AUTOSAR XML (schema 4-1-3)
standard types defined: boolean, uint8
package /UAES/ASW/CompuMethods
  compu method CM_boolean: 0=FALSE, 1=TRUE
package /UAES/ASW/DataConstrs
  range DC_boolean: raw 0..1
package /UAES/ASW/DataTypeMappingSets
  data type mapping set DTMS_HVAC_ComCnvRx
package /UAES/ASW/PortInterfaces
  53 x sender receiver interface:
    ComRx_bHVAC_AirCirculationReqVD: invalidation-policy{data-element=ComRx_bHVAC_AirCirculationReqVD/Val, handle-invalid=DONT-INVALIDATE}
      data Val: sw-calibration-access=READ-ONLY, type=boolean
    ComRx_bHVAC_DrAirCirculationReqVD: invalidation-policy{data-element=ComRx_bHVAC_DrAirCirculationReqVD/Val, handle-invalid=DONT-INVALIDATE}
      data Val: sw-calibration-access=READ-ONLY, type=boolean
    ComRx_bHVAC_DrAMDoorPostionVD: invalidation-policy{data-element=ComRx_bHVAC_DrAMDoorPostionVD/Val, handle-invalid=DONT-INVALIDATE}
      data Val: sw-calibration-access=READ-ONLY, type=boolean
    ComRx_bHVAC_PaAirCirculationReqVD: invalidation-policy{data-element=ComRx_bHVAC_PaAirCirculationReqVD/Val, handle-invalid=DONT-INVALIDATE}
      data Val: sw-calibration-access=READ-ONLY, type=boolean
    ComRx_bHVAC_PaAMDoorPostionVD: invalidation-policy{data-element=ComRx_bHVAC_PaAMDoorPostionVD/Val, handle-invalid=DONT-INVALIDATE}
      data Val: sw-calibration-access=READ-ONLY, type=boolean
    ComRx_bHVAC_RearAMDoorPosVD: invalidation-policy{data-element=ComRx_bHVAC_RearAMDoorPosVD/Val, handle-invalid=DONT-INVALIDATE}
      data Val: sw-calibration-access=READ-ONLY, type=boolean
    ComRx_bHVAC_RearDefrostSt: invalidation-policy{data-element=ComRx_bHVAC_RearDefrostSt/Val, handle-invalid=DONT-INVALIDATE}
      data Val: sw-calibration-access=READ-ONLY, type=boolean
    ComRx_bHVAC_RearWindExitModeReqVD: invalidation-policy{data-element=ComRx_bHVAC_RearWindExitModeReqVD/Val, handle-invalid=DONT-INVALIDATE}
      data Val: sw-calibration-access=READ-ONLY, type=boolean
    ComRx_bHVAC_WindExitModeReqVD: invalidation-policy{data-element=ComRx_bHVAC_WindExitModeReqVD/Val, handle-invalid=DONT-INVALIDATE}
      data Val: sw-calibration-access=READ-ONLY, type=boolean
    ComRx_u8HVAC_AirCirculationReq: invalidation-policy{data-element=ComRx_u8HVAC_AirCirculationReq/Val, handle-invalid=DONT-INVALIDATE}
      data Val: sw-calibration-access=READ-ONLY, type=uint8
    ComRx_u8HVAC_AirCirculationSt: invalidation-policy{data-element=ComRx_u8HVAC_AirCirculationSt/Val, handle-invalid=DONT-INVALIDATE}
      data Val: sw-calibration-access=READ-ONLY, type=uint8
    ComRx_u8HVAC_DrAirCirculationReq: invalidation-policy{data-element=ComRx_u8HVAC_DrAirCirculationReq/Val, handle-invalid=DONT-INVALIDATE}
      data Val: sw-calibration-access=READ-ONLY, type=uint8
    ComRx_u8HVAC_DrAMDoorPostion: invalidation-policy{data-element=ComRx_u8HVAC_DrAMDoorPostion/Val, handle-invalid=DONT-INVALIDATE}
      data Val: sw-calibration-access=READ-ONLY, type=uint8
    ComRx_u8HVAC_PaAirCirculationReq: invalidation-policy{data-element=ComRx_u8HVAC_PaAirCirculationReq/Val, handle-invalid=DONT-INVALIDATE}
      data Val: sw-calibration-access=READ-ONLY, type=uint8
    ComRx_u8HVAC_PaAMDoorPostion: invalidation-policy{data-element=ComRx_u8HVAC_PaAMDoorPostion/Val, handle-invalid=DONT-INVALIDATE}
      data Val: sw-calibration-access=READ-ONLY, type=uint8
    ComRx_u8HVAC_RearAMDoorPos: invalidation-policy{data-element=ComRx_u8HVAC_RearAMDoorPos/Val, handle-invalid=DONT-INVALIDATE}
      data Val: sw-calibration-access=READ-ONLY, type=uint8
    ComRx_u8HVAC_RearWindExitModeReq: invalidation-policy{data-element=ComRx_u8HVAC_RearWindExitModeReq/Val, handle-invalid=DONT-INVALIDATE}
      data Val: sw-calibration-access=READ-ONLY, type=uint8
    ComRx_u8HVAC_RearWindExitSpdLvl: invalidation-policy{data-element=ComRx_u8HVAC_RearWindExitSpdLvl/Val, handle-invalid=DONT-INVALIDATE}
      data Val: sw-calibration-access=READ-ONLY, type=uint8
    ComRx_u8HVAC_WindExitMode: invalidation-policy{data-element=ComRx_u8HVAC_WindExitMode/Val, handle-invalid=DONT-INVALIDATE}
      data Val: sw-calibration-access=READ-ONLY, type=uint8
    ComRx_u8HVAC_WindExitModeReq: invalidation-policy{data-element=ComRx_u8HVAC_WindExitModeReq/Val, handle-invalid=DONT-INVALIDATE}
      data Val: sw-calibration-access=READ-ONLY, type=uint8
    ComRx_u8HVAC_WindExitSpd: invalidation-policy{data-element=ComRx_u8HVAC_WindExitSpd/Val, handle-invalid=DONT-INVALIDATE}
      data Val: sw-calibration-access=READ-ONLY, type=uint8
    ComRx_u8HVAC_WindExitSpdLvl: invalidation-policy{data-element=ComRx_u8HVAC_WindExitSpdLvl/Val, handle-invalid=DONT-INVALIDATE}
      data Val: sw-calibration-access=READ-ONLY, type=uint8
    ComRx_u8UMM_UsageModeSt: invalidation-policy{data-element=ComRx_u8UMM_UsageModeSt/Val, handle-invalid=DONT-INVALIDATE}
      data Val: sw-calibration-access=READ-ONLY, type=uint8
    gASI_bCCULostCommon: invalidation-policy{data-element=gASI_bCCULostCommon/Val, handle-invalid=DONT-INVALIDATE}
      data Val: sw-calibration-access=READ-ONLY, type=boolean
    gCFG_u8BlowrCtrlFreqTyp: invalidation-policy{data-element=gCFG_u8BlowrCtrlFreqTyp/Val, handle-invalid=DONT-INVALIDATE}
      data Val: sw-calibration-access=READ-ONLY, type=uint8
    gCFG_u8BlowrCtrlTyp: invalidation-policy{data-element=gCFG_u8BlowrCtrlTyp/Val, handle-invalid=DONT-INVALIDATE}
      data Val: sw-calibration-access=READ-ONLY, type=uint8
    gCFG_u8ReBlowrCtrlFreqTyp: invalidation-policy{data-element=gCFG_u8ReBlowrCtrlFreqTyp/Val, handle-invalid=DONT-INVALIDATE}
      data Val: sw-calibration-access=READ-ONLY, type=uint8
    gCFG_u8ReBlowrCtrlTyp: invalidation-policy{data-element=gCFG_u8ReBlowrCtrlTyp/Val, handle-invalid=DONT-INVALIDATE}
      data Val: sw-calibration-access=READ-ONLY, type=uint8
    gCFG_u8ReHVACBoxTyp: invalidation-policy{data-element=gCFG_u8ReHVACBoxTyp/Val, handle-invalid=DONT-INVALIDATE}
      data Val: sw-calibration-access=READ-ONLY, type=uint8
    gPRM_u8AirConditionBoxSpecCfg: invalidation-policy{data-element=gPRM_u8AirConditionBoxSpecCfg/Val, handle-invalid=DONT-INVALIDATE}
      data Val: sw-calibration-access=READ-ONLY, type=uint8
    gPRM_u8ReAirConditionBoxSpecCfg: invalidation-policy{data-element=gPRM_u8ReAirConditionBoxSpecCfg/Val, handle-invalid=DONT-INVALIDATE}
      data Val: sw-calibration-access=READ-ONLY, type=uint8
    gPRM_u8VehicleTypeCfg: invalidation-policy{data-element=gPRM_u8VehicleTypeCfg/Val, handle-invalid=DONT-INVALIDATE}
      data Val: sw-calibration-access=READ-ONLY, range raw 0..255, type=uint8
    HvacBlowr_stReWindExitSpdLvl: invalidation-policy{data-element=HvacBlowr_stReWindExitSpdLvl/Val, handle-invalid=DONT-INVALIDATE}
      data Val: sw-calibration-access=READ-ONLY, type=uint8
    HvacBlowr_stWindExitSpdLvl: invalidation-policy{data-element=HvacBlowr_stWindExitSpdLvl/Val, handle-invalid=DONT-INVALIDATE}
      data Val: sw-calibration-access=READ-ONLY, type=uint8
    HvacDampr_bReqVldDrvrMixMot: invalidation-policy{data-element=HvacDampr_bReqVldDrvrMixMot/Val, handle-invalid=DONT-INVALIDATE}
      data Val: sw-calibration-access=READ-ONLY, type=boolean
    HvacDampr_bReqVldDrvrRcrltnMot: invalidation-policy{data-element=HvacDampr_bReqVldDrvrRcrltnMot/Val, handle-invalid=DONT-INVALIDATE}
      data Val: sw-calibration-access=READ-ONLY, type=boolean
    HvacDampr_bReqVldMotMot: invalidation-policy{data-element=HvacDampr_bReqVldMotMot/Val, handle-invalid=DONT-INVALIDATE}
      data Val: sw-calibration-access=READ-ONLY, type=boolean
    HvacDampr_bReqVldPassMixMot: invalidation-policy{data-element=HvacDampr_bReqVldPassMixMot/Val, handle-invalid=DONT-INVALIDATE}
      data Val: sw-calibration-access=READ-ONLY, type=boolean
    HvacDampr_bReqVldPassRcrltnMot: invalidation-policy{data-element=HvacDampr_bReqVldPassRcrltnMot/Val, handle-invalid=DONT-INVALIDATE}
      data Val: sw-calibration-access=READ-ONLY, type=boolean
    HvacDampr_bReqVldRcrltnMot: invalidation-policy{data-element=HvacDampr_bReqVldRcrltnMot/Val, handle-invalid=DONT-INVALIDATE}
      data Val: sw-calibration-access=READ-ONLY, type=boolean
    HvacDampr_bReqVldReMixMot: invalidation-policy{data-element=HvacDampr_bReqVldReMixMot/Val, handle-invalid=DONT-INVALIDATE}
      data Val: sw-calibration-access=READ-ONLY, type=boolean
    HvacDampr_bReqVldReMotMot: invalidation-policy{data-element=HvacDampr_bReqVldReMotMot/Val, handle-invalid=DONT-INVALIDATE}
      data Val: sw-calibration-access=READ-ONLY, type=boolean
    HvacDampr_stReqDrvrMixMot: invalidation-policy{data-element=HvacDampr_stReqDrvrMixMot/Val, handle-invalid=DONT-INVALIDATE}
      data Val: sw-calibration-access=READ-ONLY, type=uint8
    HvacDampr_stReqDrvrRcrltnMot: invalidation-policy{data-element=HvacDampr_stReqDrvrRcrltnMot/Val, handle-invalid=DONT-INVALIDATE}
      data Val: sw-calibration-access=READ-ONLY, type=uint8
    HvacDampr_stReqMotMot: invalidation-policy{data-element=HvacDampr_stReqMotMot/Val, handle-invalid=DONT-INVALIDATE}
      data Val: sw-calibration-access=READ-ONLY, type=uint8
    HvacDampr_stReqPassMixMot: invalidation-policy{data-element=HvacDampr_stReqPassMixMot/Val, handle-invalid=DONT-INVALIDATE}
      data Val: sw-calibration-access=READ-ONLY, type=uint8
    HvacDampr_stReqPassRcrltnMot: invalidation-policy{data-element=HvacDampr_stReqPassRcrltnMot/Val, handle-invalid=DONT-INVALIDATE}
      data Val: sw-calibration-access=READ-ONLY, type=uint8
    HvacDampr_stReqRcrltnMot: invalidation-policy{data-element=HvacDampr_stReqRcrltnMot/Val, handle-invalid=DONT-INVALIDATE}
      data Val: sw-calibration-access=READ-ONLY, type=uint8
    HvacDampr_stReqReMixMot: invalidation-policy{data-element=HvacDampr_stReqReMixMot/Val, handle-invalid=DONT-INVALIDATE}
      data Val: sw-calibration-access=READ-ONLY, type=uint8
    HvacDampr_stReqReMotMot: invalidation-policy{data-element=HvacDampr_stReqReMotMot/Val, handle-invalid=DONT-INVALIDATE}
      data Val: sw-calibration-access=READ-ONLY, type=uint8
    ReMirrHeatg_stReqLe: invalidation-policy{data-element=ReMirrHeatg_stReqLe/Val, handle-invalid=DONT-INVALIDATE}
      data Val: sw-calibration-access=READ-ONLY, type=uint8
    ReMirrHeatg_stReqRi: invalidation-policy{data-element=ReMirrHeatg_stReqRi/Val, handle-invalid=DONT-INVALIDATE}
      data Val: sw-calibration-access=READ-ONLY, type=uint8
    WndshdHeatg_stReqRe: invalidation-policy{data-element=WndshdHeatg_stReqRe/Val, handle-invalid=DONT-INVALIDATE}
      data Val: sw-calibration-access=READ-ONLY, type=uint8
package /UAES/ASW/SwComponentTypes
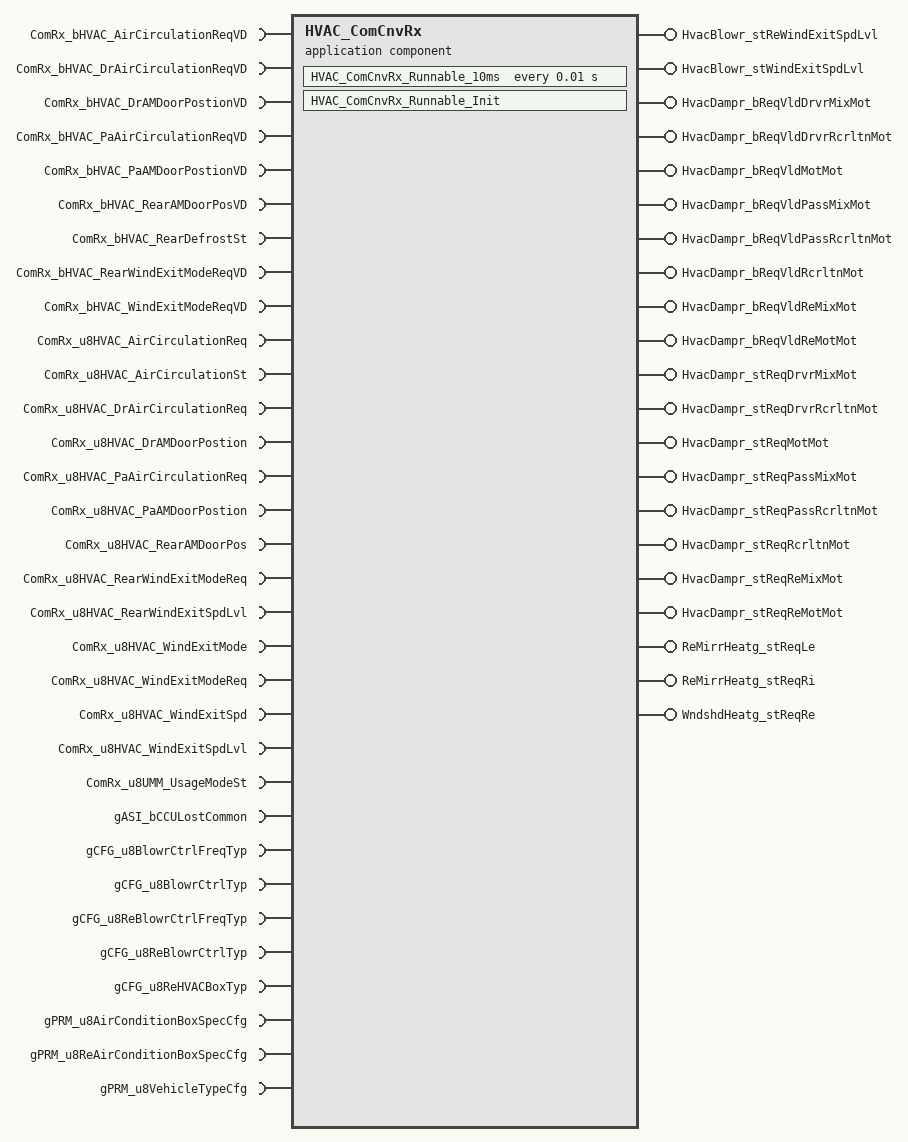
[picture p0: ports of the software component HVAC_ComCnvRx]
  application sw component type HVAC_ComCnvRx
    21 x provide port:
      HvacBlowr_stReWindExitSpdLvl: nonqueued-sender-com-spec{data-element=HvacBlowr_stReWindExitSpdLvl/Val, init-value=0}, provided-interface=HvacBlowr_stReWindExitSpdLvl
      HvacBlowr_stWindExitSpdLvl: nonqueued-sender-com-spec{data-element=HvacBlowr_stWindExitSpdLvl/Val, init-value=0}, provided-interface=HvacBlowr_stWindExitSpdLvl
      HvacDampr_bReqVldDrvrMixMot: nonqueued-sender-com-spec{data-element=HvacDampr_bReqVldDrvrMixMot/Val, init-value=0}, provided-interface=HvacDampr_bReqVldDrvrMixMot
      HvacDampr_bReqVldDrvrRcrltnMot: nonqueued-sender-com-spec{data-element=HvacDampr_bReqVldDrvrRcrltnMot/Val, init-value=0}, provided-interface=HvacDampr_bReqVldDrvrRcrltnMot
      HvacDampr_bReqVldMotMot: nonqueued-sender-com-spec{data-element=HvacDampr_bReqVldMotMot/Val, init-value=0}, provided-interface=HvacDampr_bReqVldMotMot
      HvacDampr_bReqVldPassMixMot: nonqueued-sender-com-spec{data-element=HvacDampr_bReqVldPassMixMot/Val, init-value=0}, provided-interface=HvacDampr_bReqVldPassMixMot
      HvacDampr_bReqVldPassRcrltnMot: nonqueued-sender-com-spec{data-element=HvacDampr_bReqVldPassRcrltnMot/Val, init-value=0}, provided-interface=HvacDampr_bReqVldPassRcrltnMot
      HvacDampr_bReqVldRcrltnMot: nonqueued-sender-com-spec{data-element=HvacDampr_bReqVldRcrltnMot/Val, init-value=0}, provided-interface=HvacDampr_bReqVldRcrltnMot
      HvacDampr_bReqVldReMixMot: nonqueued-sender-com-spec{data-element=HvacDampr_bReqVldReMixMot/Val, init-value=0}, provided-interface=HvacDampr_bReqVldReMixMot
      HvacDampr_bReqVldReMotMot: nonqueued-sender-com-spec{data-element=HvacDampr_bReqVldReMotMot/Val, init-value=0}, provided-interface=HvacDampr_bReqVldReMotMot
      HvacDampr_stReqDrvrMixMot: nonqueued-sender-com-spec{data-element=HvacDampr_stReqDrvrMixMot/Val, init-value=0}, provided-interface=HvacDampr_stReqDrvrMixMot
      HvacDampr_stReqDrvrRcrltnMot: nonqueued-sender-com-spec{data-element=HvacDampr_stReqDrvrRcrltnMot/Val, init-value=0}, provided-interface=HvacDampr_stReqDrvrRcrltnMot
      HvacDampr_stReqMotMot: nonqueued-sender-com-spec{data-element=HvacDampr_stReqMotMot/Val, init-value=0}, provided-interface=HvacDampr_stReqMotMot
      HvacDampr_stReqPassMixMot: nonqueued-sender-com-spec{data-element=HvacDampr_stReqPassMixMot/Val, init-value=0}, provided-interface=HvacDampr_stReqPassMixMot
      HvacDampr_stReqPassRcrltnMot: nonqueued-sender-com-spec{data-element=HvacDampr_stReqPassRcrltnMot/Val, init-value=0}, provided-interface=HvacDampr_stReqPassRcrltnMot
      HvacDampr_stReqRcrltnMot: nonqueued-sender-com-spec{data-element=HvacDampr_stReqRcrltnMot/Val, init-value=0}, provided-interface=HvacDampr_stReqRcrltnMot
      HvacDampr_stReqReMixMot: nonqueued-sender-com-spec{data-element=HvacDampr_stReqReMixMot/Val, init-value=0}, provided-interface=HvacDampr_stReqReMixMot
      HvacDampr_stReqReMotMot: nonqueued-sender-com-spec{data-element=HvacDampr_stReqReMotMot/Val, init-value=0}, provided-interface=HvacDampr_stReqReMotMot
      ReMirrHeatg_stReqLe: nonqueued-sender-com-spec{data-element=ReMirrHeatg_stReqLe/Val, init-value=0}, provided-interface=ReMirrHeatg_stReqLe
      ReMirrHeatg_stReqRi: nonqueued-sender-com-spec{data-element=ReMirrHeatg_stReqRi/Val, init-value=0}, provided-interface=ReMirrHeatg_stReqRi
      WndshdHeatg_stReqRe: nonqueued-sender-com-spec{data-element=WndshdHeatg_stReqRe/Val, init-value=0}, provided-interface=WndshdHeatg_stReqRe
    32 x require port:
      ComRx_bHVAC_AirCirculationReqVD: nonqueued-receiver-com-spec{data-element=ComRx_bHVAC_AirCirculationReqVD/Val, filter=data-filter-type=ALWAYS, init-value=0}, required-interface=ComRx_bHVAC_AirCirculationReqVD
      ComRx_bHVAC_DrAirCirculationReqVD: nonqueued-receiver-com-spec{data-element=ComRx_bHVAC_DrAirCirculationReqVD/Val, filter=data-filter-type=ALWAYS, init-value=0}, required-interface=ComRx_bHVAC_DrAirCirculationReqVD
      ComRx_bHVAC_DrAMDoorPostionVD: nonqueued-receiver-com-spec{data-element=ComRx_bHVAC_DrAMDoorPostionVD/Val, filter=data-filter-type=ALWAYS, init-value=0}, required-interface=ComRx_bHVAC_DrAMDoorPostionVD
      ComRx_bHVAC_PaAirCirculationReqVD: nonqueued-receiver-com-spec{data-element=ComRx_bHVAC_PaAirCirculationReqVD/Val, filter=data-filter-type=ALWAYS, init-value=0}, required-interface=ComRx_bHVAC_PaAirCirculationReqVD
      ComRx_bHVAC_PaAMDoorPostionVD: nonqueued-receiver-com-spec{data-element=ComRx_bHVAC_PaAMDoorPostionVD/Val, filter=data-filter-type=ALWAYS, init-value=0}, required-interface=ComRx_bHVAC_PaAMDoorPostionVD
      ComRx_bHVAC_RearAMDoorPosVD: nonqueued-receiver-com-spec{data-element=ComRx_bHVAC_RearAMDoorPosVD/Val, filter=data-filter-type=ALWAYS, init-value=0}, required-interface=ComRx_bHVAC_RearAMDoorPosVD
      ComRx_bHVAC_RearDefrostSt: nonqueued-receiver-com-spec{data-element=ComRx_bHVAC_RearDefrostSt/Val, filter=data-filter-type=ALWAYS, init-value=0}, required-interface=ComRx_bHVAC_RearDefrostSt
      ComRx_bHVAC_RearWindExitModeReqVD: nonqueued-receiver-com-spec{data-element=ComRx_bHVAC_RearWindExitModeReqVD/Val, filter=data-filter-type=ALWAYS, init-value=0}, required-interface=ComRx_bHVAC_RearWindExitModeReqVD
      ComRx_bHVAC_WindExitModeReqVD: nonqueued-receiver-com-spec{data-element=ComRx_bHVAC_WindExitModeReqVD/Val, filter=data-filter-type=ALWAYS, init-value=0}, required-interface=ComRx_bHVAC_WindExitModeReqVD
      ComRx_u8HVAC_AirCirculationReq: nonqueued-receiver-com-spec{data-element=ComRx_u8HVAC_AirCirculationReq/Val, filter=data-filter-type=ALWAYS, init-value=0}, required-interface=ComRx_u8HVAC_AirCirculationReq
      ComRx_u8HVAC_AirCirculationSt: nonqueued-receiver-com-spec{data-element=ComRx_u8HVAC_AirCirculationSt/Val, filter=data-filter-type=ALWAYS, init-value=0}, required-interface=ComRx_u8HVAC_AirCirculationSt
      ComRx_u8HVAC_DrAirCirculationReq: nonqueued-receiver-com-spec{data-element=ComRx_u8HVAC_DrAirCirculationReq/Val, filter=data-filter-type=ALWAYS, init-value=0}, required-interface=ComRx_u8HVAC_DrAirCirculationReq
      ComRx_u8HVAC_DrAMDoorPostion: nonqueued-receiver-com-spec{data-element=ComRx_u8HVAC_DrAMDoorPostion/Val, filter=data-filter-type=ALWAYS, init-value=0}, required-interface=ComRx_u8HVAC_DrAMDoorPostion
      ComRx_u8HVAC_PaAirCirculationReq: nonqueued-receiver-com-spec{data-element=ComRx_u8HVAC_PaAirCirculationReq/Val, filter=data-filter-type=ALWAYS, init-value=0}, required-interface=ComRx_u8HVAC_PaAirCirculationReq
      ComRx_u8HVAC_PaAMDoorPostion: nonqueued-receiver-com-spec{data-element=ComRx_u8HVAC_PaAMDoorPostion/Val, filter=data-filter-type=ALWAYS, init-value=0}, required-interface=ComRx_u8HVAC_PaAMDoorPostion
      ComRx_u8HVAC_RearAMDoorPos: nonqueued-receiver-com-spec{data-element=ComRx_u8HVAC_RearAMDoorPos/Val, filter=data-filter-type=ALWAYS, init-value=0}, required-interface=ComRx_u8HVAC_RearAMDoorPos
      ComRx_u8HVAC_RearWindExitModeReq: nonqueued-receiver-com-spec{data-element=ComRx_u8HVAC_RearWindExitModeReq/Val, filter=data-filter-type=ALWAYS, init-value=0}, required-interface=ComRx_u8HVAC_RearWindExitModeReq
      ComRx_u8HVAC_RearWindExitSpdLvl: nonqueued-receiver-com-spec{data-element=ComRx_u8HVAC_RearWindExitSpdLvl/Val, filter=data-filter-type=ALWAYS, init-value=0}, required-interface=ComRx_u8HVAC_RearWindExitSpdLvl
      ComRx_u8HVAC_WindExitMode: nonqueued-receiver-com-spec{data-element=ComRx_u8HVAC_WindExitMode/Val, filter=data-filter-type=ALWAYS, init-value=0}, required-interface=ComRx_u8HVAC_WindExitMode
      ComRx_u8HVAC_WindExitModeReq: nonqueued-receiver-com-spec{data-element=ComRx_u8HVAC_WindExitModeReq/Val, filter=data-filter-type=ALWAYS, init-value=0}, required-interface=ComRx_u8HVAC_WindExitModeReq
      ComRx_u8HVAC_WindExitSpd: nonqueued-receiver-com-spec{data-element=ComRx_u8HVAC_WindExitSpd/Val, filter=data-filter-type=ALWAYS, init-value=0}, required-interface=ComRx_u8HVAC_WindExitSpd
      ComRx_u8HVAC_WindExitSpdLvl: nonqueued-receiver-com-spec{data-element=ComRx_u8HVAC_WindExitSpdLvl/Val, filter=data-filter-type=ALWAYS, init-value=0}, required-interface=ComRx_u8HVAC_WindExitSpdLvl
      ComRx_u8UMM_UsageModeSt: nonqueued-receiver-com-spec{data-element=ComRx_u8UMM_UsageModeSt/Val, filter=data-filter-type=ALWAYS, init-value=0}, required-interface=ComRx_u8UMM_UsageModeSt
      gASI_bCCULostCommon: nonqueued-receiver-com-spec{data-element=gASI_bCCULostCommon/Val, filter=data-filter-type=ALWAYS, init-value=0}, required-interface=gASI_bCCULostCommon
      gCFG_u8BlowrCtrlFreqTyp: nonqueued-receiver-com-spec{data-element=gCFG_u8BlowrCtrlFreqTyp/Val, filter=data-filter-type=ALWAYS, init-value=0}, required-interface=gCFG_u8BlowrCtrlFreqTyp
      gCFG_u8BlowrCtrlTyp: nonqueued-receiver-com-spec{data-element=gCFG_u8BlowrCtrlTyp/Val, filter=data-filter-type=ALWAYS, init-value=0}, required-interface=gCFG_u8BlowrCtrlTyp
      gCFG_u8ReBlowrCtrlFreqTyp: nonqueued-receiver-com-spec{data-element=gCFG_u8ReBlowrCtrlFreqTyp/Val, filter=data-filter-type=ALWAYS, init-value=0}, required-interface=gCFG_u8ReBlowrCtrlFreqTyp
      gCFG_u8ReBlowrCtrlTyp: nonqueued-receiver-com-spec{data-element=gCFG_u8ReBlowrCtrlTyp/Val, filter=data-filter-type=ALWAYS, init-value=0}, required-interface=gCFG_u8ReBlowrCtrlTyp
      gCFG_u8ReHVACBoxTyp: nonqueued-receiver-com-spec{data-element=gCFG_u8ReHVACBoxTyp/Val, filter=data-filter-type=ALWAYS, init-value=0}, required-interface=gCFG_u8ReHVACBoxTyp
      gPRM_u8AirConditionBoxSpecCfg: nonqueued-receiver-com-spec{data-element=gPRM_u8AirConditionBoxSpecCfg/Val, filter=data-filter-type=ALWAYS, init-value=0}, required-interface=gPRM_u8AirConditionBoxSpecCfg
      gPRM_u8ReAirConditionBoxSpecCfg: nonqueued-receiver-com-spec{data-element=gPRM_u8ReAirConditionBoxSpecCfg/Val, filter=data-filter-type=ALWAYS, init-value=0}, required-interface=gPRM_u8ReAirConditionBoxSpecCfg
      gPRM_u8VehicleTypeCfg: nonqueued-receiver-com-spec{data-element=gPRM_u8VehicleTypeCfg/Val, filter=data-filter-type=ALWAYS, init-value=0}, required-interface=gPRM_u8VehicleTypeCfg
    behavior HVAC_ComCnvRx_InternalBehavior: data-type-mapping=DTMS_HVAC_ComCnvRx
      timing event TMT_HVAC_ComCnvRx_Runnable_10ms: start-on-event=HVAC_ComCnvRx_Runnable_10ms, period=0.01
      init event HVAC_ComCnvRx_Runnable_InitEvent: start-on-event=HVAC_ComCnvRx_Runnable_Init
      runnable HVAC_ComCnvRx_Runnable_10ms
        data-receive-point-by-arguments:
          32 x access:
            IN_ComRx_bHVAC_AirCirculationReqVD_Val: accessed-variable=ComRx_bHVAC_AirCirculationReqVD.Val
            IN_ComRx_bHVAC_DrAirCirculationReqVD_Val: accessed-variable=ComRx_bHVAC_DrAirCirculationReqVD.Val
            IN_ComRx_bHVAC_DrAMDoorPostionVD_Val: accessed-variable=ComRx_bHVAC_DrAMDoorPostionVD.Val
            IN_ComRx_bHVAC_PaAirCirculationReqVD_Val: accessed-variable=ComRx_bHVAC_PaAirCirculationReqVD.Val
            IN_ComRx_bHVAC_PaAMDoorPostionVD_Val: accessed-variable=ComRx_bHVAC_PaAMDoorPostionVD.Val
            IN_ComRx_bHVAC_RearAMDoorPosVD_Val: accessed-variable=ComRx_bHVAC_RearAMDoorPosVD.Val
            IN_ComRx_bHVAC_RearDefrostSt_Val: accessed-variable=ComRx_bHVAC_RearDefrostSt.Val
            IN_ComRx_bHVAC_RearWindExitModeReqVD_Val: accessed-variable=ComRx_bHVAC_RearWindExitModeReqVD.Val
            IN_ComRx_bHVAC_WindExitModeReqVD_Val: accessed-variable=ComRx_bHVAC_WindExitModeReqVD.Val
            IN_ComRx_u8HVAC_AirCirculationReq_Val: accessed-variable=ComRx_u8HVAC_AirCirculationReq.Val
            IN_ComRx_u8HVAC_AirCirculationSt_Val: accessed-variable=ComRx_u8HVAC_AirCirculationSt.Val
            IN_ComRx_u8HVAC_DrAirCirculationReq_Val: accessed-variable=ComRx_u8HVAC_DrAirCirculationReq.Val
            IN_ComRx_u8HVAC_DrAMDoorPostion_Val: accessed-variable=ComRx_u8HVAC_DrAMDoorPostion.Val
            IN_ComRx_u8HVAC_PaAirCirculationReq_Val: accessed-variable=ComRx_u8HVAC_PaAirCirculationReq.Val
            IN_ComRx_u8HVAC_PaAMDoorPostion_Val: accessed-variable=ComRx_u8HVAC_PaAMDoorPostion.Val
            IN_ComRx_u8HVAC_RearAMDoorPos_Val: accessed-variable=ComRx_u8HVAC_RearAMDoorPos.Val
            IN_ComRx_u8HVAC_RearWindExitModeReq_Val: accessed-variable=ComRx_u8HVAC_RearWindExitModeReq.Val
            IN_ComRx_u8HVAC_RearWindExitSpdLvl_Val: accessed-variable=ComRx_u8HVAC_RearWindExitSpdLvl.Val
            IN_ComRx_u8HVAC_WindExitMode_Val: accessed-variable=ComRx_u8HVAC_WindExitMode.Val
            IN_ComRx_u8HVAC_WindExitModeReq_Val: accessed-variable=ComRx_u8HVAC_WindExitModeReq.Val
            IN_ComRx_u8HVAC_WindExitSpd_Val: accessed-variable=ComRx_u8HVAC_WindExitSpd.Val
            IN_ComRx_u8HVAC_WindExitSpdLvl_Val: accessed-variable=ComRx_u8HVAC_WindExitSpdLvl.Val
            IN_ComRx_u8UMM_UsageModeSt_Val: accessed-variable=ComRx_u8UMM_UsageModeSt.Val
            IN_gASI_bCCULostCommon_Val: accessed-variable=gASI_bCCULostCommon.Val
            IN_gCFG_u8BlowrCtrlFreqTyp_Val: accessed-variable=gCFG_u8BlowrCtrlFreqTyp.Val
            IN_gCFG_u8BlowrCtrlTyp_Val: accessed-variable=gCFG_u8BlowrCtrlTyp.Val
            IN_gCFG_u8ReBlowrCtrlFreqTyp_Val: accessed-variable=gCFG_u8ReBlowrCtrlFreqTyp.Val
            IN_gCFG_u8ReBlowrCtrlTyp_Val: accessed-variable=gCFG_u8ReBlowrCtrlTyp.Val
            IN_gCFG_u8ReHVACBoxTyp_Val: accessed-variable=gCFG_u8ReHVACBoxTyp.Val
            IN_gPRM_u8AirConditionBoxSpecCfg_Val: accessed-variable=gPRM_u8AirConditionBoxSpecCfg.Val
            IN_gPRM_u8ReAirConditionBoxSpecCfg_Val: accessed-variable=gPRM_u8ReAirConditionBoxSpecCfg.Val
            IN_gPRM_u8VehicleTypeCfg_Val: accessed-variable=gPRM_u8VehicleTypeCfg.Val
        data-send-points:
          21 x access:
            OUT_HvacBlowr_stReWindExitSpdLvl_Val: accessed-variable=HvacBlowr_stReWindExitSpdLvl.Val
            OUT_HvacBlowr_stWindExitSpdLvl_Val: accessed-variable=HvacBlowr_stWindExitSpdLvl.Val
            OUT_HvacDampr_bReqVldDrvrMixMot_Val: accessed-variable=HvacDampr_bReqVldDrvrMixMot.Val
            OUT_HvacDampr_bReqVldDrvrRcrltnMot_Val: accessed-variable=HvacDampr_bReqVldDrvrRcrltnMot.Val
            OUT_HvacDampr_bReqVldMotMot_Val: accessed-variable=HvacDampr_bReqVldMotMot.Val
            OUT_HvacDampr_bReqVldPassMixMot_Val: accessed-variable=HvacDampr_bReqVldPassMixMot.Val
            OUT_HvacDampr_bReqVldPassRcrltnMot_Val: accessed-variable=HvacDampr_bReqVldPassRcrltnMot.Val
            OUT_HvacDampr_bReqVldRcrltnMot_Val: accessed-variable=HvacDampr_bReqVldRcrltnMot.Val
            OUT_HvacDampr_bReqVldReMixMot_Val: accessed-variable=HvacDampr_bReqVldReMixMot.Val
            OUT_HvacDampr_bReqVldReMotMot_Val: accessed-variable=HvacDampr_bReqVldReMotMot.Val
            OUT_HvacDampr_stReqDrvrMixMot_Val: accessed-variable=HvacDampr_stReqDrvrMixMot.Val
            OUT_HvacDampr_stReqDrvrRcrltnMot_Val: accessed-variable=HvacDampr_stReqDrvrRcrltnMot.Val
            OUT_HvacDampr_stReqMotMot_Val: accessed-variable=HvacDampr_stReqMotMot.Val
            OUT_HvacDampr_stReqPassMixMot_Val: accessed-variable=HvacDampr_stReqPassMixMot.Val
            OUT_HvacDampr_stReqPassRcrltnMot_Val: accessed-variable=HvacDampr_stReqPassRcrltnMot.Val
            OUT_HvacDampr_stReqRcrltnMot_Val: accessed-variable=HvacDampr_stReqRcrltnMot.Val
            OUT_HvacDampr_stReqReMixMot_Val: accessed-variable=HvacDampr_stReqReMixMot.Val
            OUT_HvacDampr_stReqReMotMot_Val: accessed-variable=HvacDampr_stReqReMotMot.Val
            OUT_ReMirrHeatg_stReqLe_Val: accessed-variable=ReMirrHeatg_stReqLe.Val
            OUT_ReMirrHeatg_stReqRi_Val: accessed-variable=ReMirrHeatg_stReqRi.Val
            OUT_WndshdHeatg_stReqRe_Val: accessed-variable=WndshdHeatg_stReqRe.Val
      runnable HVAC_ComCnvRx_Runnable_Init
        data-receive-point-by-arguments:
          32 x access:
            IN_ComRx_bHVAC_AirCirculationReqVD_Val: accessed-variable=ComRx_bHVAC_AirCirculationReqVD.Val
            IN_ComRx_bHVAC_DrAirCirculationReqVD_Val: accessed-variable=ComRx_bHVAC_DrAirCirculationReqVD.Val
            IN_ComRx_bHVAC_DrAMDoorPostionVD_Val: accessed-variable=ComRx_bHVAC_DrAMDoorPostionVD.Val
            IN_ComRx_bHVAC_PaAirCirculationReqVD_Val: accessed-variable=ComRx_bHVAC_PaAirCirculationReqVD.Val
            IN_ComRx_bHVAC_PaAMDoorPostionVD_Val: accessed-variable=ComRx_bHVAC_PaAMDoorPostionVD.Val
            IN_ComRx_bHVAC_RearAMDoorPosVD_Val: accessed-variable=ComRx_bHVAC_RearAMDoorPosVD.Val
            IN_ComRx_bHVAC_RearDefrostSt_Val: accessed-variable=ComRx_bHVAC_RearDefrostSt.Val
            IN_ComRx_bHVAC_RearWindExitModeReqVD_Val: accessed-variable=ComRx_bHVAC_RearWindExitModeReqVD.Val
            IN_ComRx_bHVAC_WindExitModeReqVD_Val: accessed-variable=ComRx_bHVAC_WindExitModeReqVD.Val
            IN_ComRx_u8HVAC_AirCirculationReq_Val: accessed-variable=ComRx_u8HVAC_AirCirculationReq.Val
            IN_ComRx_u8HVAC_AirCirculationSt_Val: accessed-variable=ComRx_u8HVAC_AirCirculationSt.Val
            IN_ComRx_u8HVAC_DrAirCirculationReq_Val: accessed-variable=ComRx_u8HVAC_DrAirCirculationReq.Val
            IN_ComRx_u8HVAC_DrAMDoorPostion_Val: accessed-variable=ComRx_u8HVAC_DrAMDoorPostion.Val
            IN_ComRx_u8HVAC_PaAirCirculationReq_Val: accessed-variable=ComRx_u8HVAC_PaAirCirculationReq.Val
            IN_ComRx_u8HVAC_PaAMDoorPostion_Val: accessed-variable=ComRx_u8HVAC_PaAMDoorPostion.Val
            IN_ComRx_u8HVAC_RearAMDoorPos_Val: accessed-variable=ComRx_u8HVAC_RearAMDoorPos.Val
            IN_ComRx_u8HVAC_RearWindExitModeReq_Val: accessed-variable=ComRx_u8HVAC_RearWindExitModeReq.Val
            IN_ComRx_u8HVAC_RearWindExitSpdLvl_Val: accessed-variable=ComRx_u8HVAC_RearWindExitSpdLvl.Val
            IN_ComRx_u8HVAC_WindExitMode_Val: accessed-variable=ComRx_u8HVAC_WindExitMode.Val
            IN_ComRx_u8HVAC_WindExitModeReq_Val: accessed-variable=ComRx_u8HVAC_WindExitModeReq.Val
            IN_ComRx_u8HVAC_WindExitSpd_Val: accessed-variable=ComRx_u8HVAC_WindExitSpd.Val
            IN_ComRx_u8HVAC_WindExitSpdLvl_Val: accessed-variable=ComRx_u8HVAC_WindExitSpdLvl.Val
            IN_ComRx_u8UMM_UsageModeSt_Val: accessed-variable=ComRx_u8UMM_UsageModeSt.Val
            IN_gASI_bCCULostCommon_Val: accessed-variable=gASI_bCCULostCommon.Val
            IN_gCFG_u8BlowrCtrlFreqTyp_Val: accessed-variable=gCFG_u8BlowrCtrlFreqTyp.Val
            IN_gCFG_u8BlowrCtrlTyp_Val: accessed-variable=gCFG_u8BlowrCtrlTyp.Val
            IN_gCFG_u8ReBlowrCtrlFreqTyp_Val: accessed-variable=gCFG_u8ReBlowrCtrlFreqTyp.Val
            IN_gCFG_u8ReBlowrCtrlTyp_Val: accessed-variable=gCFG_u8ReBlowrCtrlTyp.Val
            IN_gCFG_u8ReHVACBoxTyp_Val: accessed-variable=gCFG_u8ReHVACBoxTyp.Val
            IN_gPRM_u8AirConditionBoxSpecCfg_Val: accessed-variable=gPRM_u8AirConditionBoxSpecCfg.Val
            IN_gPRM_u8ReAirConditionBoxSpecCfg_Val: accessed-variable=gPRM_u8ReAirConditionBoxSpecCfg.Val
            IN_gPRM_u8VehicleTypeCfg_Val: accessed-variable=gPRM_u8VehicleTypeCfg.Val
        data-send-points:
          21 x access:
            OUT_HvacBlowr_stReWindExitSpdLvl_Val: accessed-variable=HvacBlowr_stReWindExitSpdLvl.Val
            OUT_HvacBlowr_stWindExitSpdLvl_Val: accessed-variable=HvacBlowr_stWindExitSpdLvl.Val
            OUT_HvacDampr_bReqVldDrvrMixMot_Val: accessed-variable=HvacDampr_bReqVldDrvrMixMot.Val
            OUT_HvacDampr_bReqVldDrvrRcrltnMot_Val: accessed-variable=HvacDampr_bReqVldDrvrRcrltnMot.Val
            OUT_HvacDampr_bReqVldMotMot_Val: accessed-variable=HvacDampr_bReqVldMotMot.Val
            OUT_HvacDampr_bReqVldPassMixMot_Val: accessed-variable=HvacDampr_bReqVldPassMixMot.Val
            OUT_HvacDampr_bReqVldPassRcrltnMot_Val: accessed-variable=HvacDampr_bReqVldPassRcrltnMot.Val
            OUT_HvacDampr_bReqVldRcrltnMot_Val: accessed-variable=HvacDampr_bReqVldRcrltnMot.Val
            OUT_HvacDampr_bReqVldReMixMot_Val: accessed-variable=HvacDampr_bReqVldReMixMot.Val
            OUT_HvacDampr_bReqVldReMotMot_Val: accessed-variable=HvacDampr_bReqVldReMotMot.Val
            OUT_HvacDampr_stReqDrvrMixMot_Val: accessed-variable=HvacDampr_stReqDrvrMixMot.Val
            OUT_HvacDampr_stReqDrvrRcrltnMot_Val: accessed-variable=HvacDampr_stReqDrvrRcrltnMot.Val
            OUT_HvacDampr_stReqMotMot_Val: accessed-variable=HvacDampr_stReqMotMot.Val
            OUT_HvacDampr_stReqPassMixMot_Val: accessed-variable=HvacDampr_stReqPassMixMot.Val
            OUT_HvacDampr_stReqPassRcrltnMot_Val: accessed-variable=HvacDampr_stReqPassRcrltnMot.Val
            OUT_HvacDampr_stReqRcrltnMot_Val: accessed-variable=HvacDampr_stReqRcrltnMot.Val
            OUT_HvacDampr_stReqReMixMot_Val: accessed-variable=HvacDampr_stReqReMixMot.Val
            OUT_HvacDampr_stReqReMotMot_Val: accessed-variable=HvacDampr_stReqReMotMot.Val
            OUT_ReMirrHeatg_stReqLe_Val: accessed-variable=ReMirrHeatg_stReqLe.Val
            OUT_ReMirrHeatg_stReqRi_Val: accessed-variable=ReMirrHeatg_stReqRi.Val
            OUT_WndshdHeatg_stReqRe_Val: accessed-variable=WndshdHeatg_stReqRe.Val
  swc implementation HVAC_ComCnvRx_Implementation: behavior=HVAC_ComCnvRx_InternalBehavior
    code-descriptors:
      code Default: artifact-descriptors=autosar-engineering-object={short-label=Default, category=SWSRC}
package /UAES/ASW/Units
  unit NoUnit: factor-si-to-unit=1, offset-si-to-unit=0
